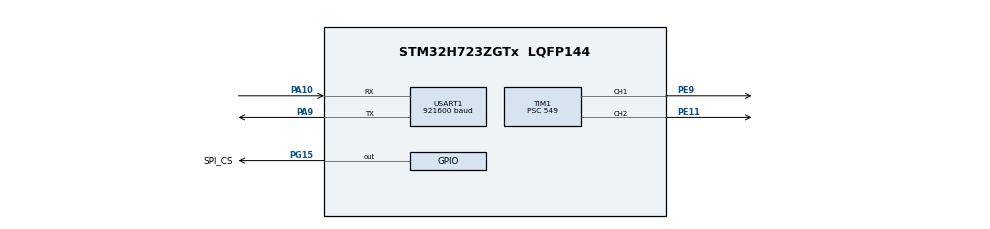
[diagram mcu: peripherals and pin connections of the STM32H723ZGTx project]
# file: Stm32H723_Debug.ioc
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Dma.Request0=USART1_RX
Dma.Request1=USART1_TX
Dma.USART1_RX.0.Direction=DMA_PERIPH_TO_MEMORY
Dma.USART1_RX.0.EventEnable=DISABLE
Dma.USART1_RX.0.FIFOMode=DMA_FIFOMODE_DISABLE
Dma.USART1_RX.0.Instance=DMA1_Stream0
Dma.USART1_RX.0.MemDataAlignment=DMA_MDATAALIGN_BYTE
Dma.USART1_RX.0.MemInc=DMA_MINC_ENABLE
Dma.USART1_RX.0.Mode=DMA_NORMAL
Dma.USART1_RX.0.PeriphDataAlignment=DMA_PDATAALIGN_BYTE
Dma.USART1_RX.0.PeriphInc=DMA_PINC_DISABLE
Dma.USART1_RX.0.Polarity=HAL_DMAMUX_REQ_GEN_RISING
Dma.USART1_RX.0.Priority=DMA_PRIORITY_LOW
Dma.USART1_RX.0.RequestNumber=1
Dma.USART1_RX.0.SignalID=NONE
Dma.USART1_RX.0.SyncEnable=DISABLE
Dma.USART1_RX.0.SyncPolarity=HAL_DMAMUX_SYNC_NO_EVENT
Dma.USART1_RX.0.SyncRequestNumber=1
Dma.USART1_RX.0.SyncSignalID=NONE
Dma.USART1_TX.1.Direction=DMA_MEMORY_TO_PERIPH
Dma.USART1_TX.1.EventEnable=DISABLE
Dma.USART1_TX.1.FIFOMode=DMA_FIFOMODE_DISABLE
Dma.USART1_TX.1.Instance=DMA1_Stream1
Dma.USART1_TX.1.MemDataAlignment=DMA_MDATAALIGN_BYTE
Dma.USART1_TX.1.MemInc=DMA_MINC_ENABLE
Dma.USART1_TX.1.Mode=DMA_NORMAL
Dma.USART1_TX.1.PeriphDataAlignment=DMA_PDATAALIGN_BYTE
Dma.USART1_TX.1.PeriphInc=DMA_PINC_DISABLE
Dma.USART1_TX.1.Polarity=HAL_DMAMUX_REQ_GEN_RISING
Dma.USART1_TX.1.Priority=DMA_PRIORITY_LOW
Dma.USART1_TX.1.RequestNumber=1
Dma.USART1_TX.1.SignalID=NONE
Dma.USART1_TX.1.SyncEnable=DISABLE
Dma.USART1_TX.1.SyncPolarity=HAL_DMAMUX_SYNC_NO_EVENT
Dma.USART1_TX.1.SyncRequestNumber=1
Dma.USART1_TX.1.SyncSignalID=NONE
FREERTOS.BinarySemaphores01=elog_lock,Dynamic,NULL;elog_async,Dynamic,NULL;elog_dma_lock,Dynamic,NULL
FREERTOS.INCLUDE_vTaskDelayUntil=1
FREERTOS.Tasks01=defaultTask,24,1024,DefaultTask,As weak,NULL,Dynamic,NULL,NULL;testTask,32,512,TestTask,As weak,NULL,Dynamic,NULL,NULL
FREERTOS.configENABLE_FPU=1
FREERTOS.configUSE_NEWLIB_REENTRANT=1
Mcu.Family=STM32H7
Mcu.Name=STM32H723ZGTx
Mcu.Package=LQFP144
NVIC.DMA1_Stream0_IRQn=true\:5\:0\:false\:false\:true\:true\:false\:true\:true
NVIC.DMA1_Stream1_IRQn=true\:5\:0\:false\:false\:true\:true\:false\:true\:true
NVIC.PriorityGroup=NVIC_PRIORITYGROUP_4
NVIC.TIM8_BRK_TIM12_IRQn=true\:15\:0\:false\:false\:true\:false\:false\:true\:true
NVIC.TimeBase=TIM8_BRK_TIM12_IRQn
NVIC.TimeBaseIP=TIM12
NVIC.USART1_IRQn=true\:5\:0\:false\:false\:true\:true\:true\:true\:true
PA10.GPIO_Speed=GPIO_SPEED_FREQ_VERY_HIGH
PA10.Mode=Asynchronous
PA10.Signal=USART1_RX
PA13(JTMS/SWDIO).Mode=Serial_Wire
PA13(JTMS/SWDIO).Signal=DEBUG_JTMS-SWDIO
PA14(JTCK/SWCLK).Mode=Serial_Wire
PA14(JTCK/SWCLK).Signal=DEBUG_JTCK-SWCLK
PA9.GPIO_Speed=GPIO_SPEED_FREQ_VERY_HIGH
PA9.Mode=Asynchronous
PA9.Signal=USART1_TX
PC14-OSC32_IN.Mode=LSE-External-Oscillator
PC14-OSC32_IN.Signal=RCC_OSC32_IN
PC15-OSC32_OUT.Mode=LSE-External-Oscillator
PC15-OSC32_OUT.Signal=RCC_OSC32_OUT
PE11.Signal=S_TIM1_CH2
PE9.Signal=S_TIM1_CH1
PF7.Signal=OCTOSPIM_P1_IO2
PG15.GPIO_Label=SPI_CS
PG15.Signal=GPIO_Output
PG6.Signal=OCTOSPIM_P1_NCS
PG8.GPIO_Speed=GPIO_SPEED_FREQ_VERY_HIGH
PG8.Signal=SPI6_NSS
PH0-OSC_IN.Mode=HSE-External-Oscillator
PH0-OSC_IN.Signal=RCC_OSC_IN
PH1-OSC_OUT.Mode=HSE-External-Oscillator
PH1-OSC_OUT.Signal=RCC_OSC_OUT
ProjectManager.HeapSize=0x1000
ProjectManager.StackSize=0x1000
ProjectManager.TargetToolchain=STM32CubeIDE
RCC.ADCFreq_Value=50390625
RCC.APB1Freq_Value=137500000
RCC.APB2Freq_Value=137500000
RCC.APB3Freq_Value=137500000
RCC.APB4Freq_Value=137500000
RCC.CortexFreq_Value=550000000
RCC.D1PPRE=RCC_APB3_DIV2
RCC.D2PPRE1=RCC_APB1_DIV2
RCC.D2PPRE2=RCC_APB2_DIV2
RCC.D3PPRE=RCC_APB4_DIV2
RCC.DIVM1=10
RCC.DIVN1=220
RCC.DIVP1=1
RCC.DIVQ1=5
RCC.HCLKFreq_Value=275000000
RCC.HPRE=RCC_HCLK_DIV2
RCC.PLLSourceVirtual=RCC_PLLSOURCE_HSE
RCC.RTCClockSelection=RCC_RTCCLKSOURCE_LSE
RCC.SYSCLKFreq_VALUE=550000000
RCC.SYSCLKSource=RCC_SYSCLKSOURCE_PLLCLK
RCC.USBCLockSelection=RCC_USBCLKSOURCE_HSI48
RCC.USBFreq_Value=48000000
SH.S_TIM1_CH1.0=TIM1_CH1,PWM Generation1 CH1
SH.S_TIM1_CH2.0=TIM1_CH2,PWM Generation2 CH2
TIM1.Channel-PWM\ Generation1\ CH1=TIM_CHANNEL_1
TIM1.Channel-PWM\ Generation2\ CH2=TIM_CHANNEL_2
TIM1.Period=100
TIM1.Prescaler=549
TIM1.Pulse-PWM\ Generation1\ CH1=50
TIM1.Pulse-PWM\ Generation2\ CH2=50
USART1.BaudRate=921600
USART1.VirtualMode-Asynchronous=VM_ASYNC
VP_FREERTOS_VS_CMSIS_V2.Mode=CMSIS_V2
VP_SYS_VS_tim12.Mode=TIM12
board=custom

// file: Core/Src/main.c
/* USER CODE BEGIN Header */
/**
  ******************************************************************************
  * @file           : main.c
  * @brief          : Main program body
  ******************************************************************************
  * @attention
  *
  * Copyright (c) 2024 STMicroelectronics.
  * All rights reserved.
  *
  * This software is licensed under terms that can be found in the LICENSE file
  * in the root directory of this software component.
  * If no LICENSE file comes with this software, it is provided AS-IS.
  *
  ******************************************************************************
  */
/* USER CODE END Header */
#include "main.h"
#include "cmsis_os.h"
#include "dma.h"
#include "tim.h"
#include "usart.h"
#include "gpio.h"

void SystemClock_Config(void);
void MX_FREERTOS_Init(void);

int main(void)
{

  /* MCU Configuration--------------------------------------------------------*/

  /* Reset of all peripherals, Initializes the Flash interface and the Systick. */
  HAL_Init();

  /* Configure the system clock */
  SystemClock_Config();

  /* Initialize all configured peripherals */
  MX_GPIO_Init();
  MX_DMA_Init();
  MX_USART1_UART_Init();
  MX_TIM1_Init();
  /* USER CODE BEGIN 2 */
  Main();

  /* USER CODE END 2 */

  /* Init scheduler */
  osKernelInitialize();

  /* Call init function for freertos objects (in cmsis_os2.c) */
  MX_FREERTOS_Init();

  /* Start scheduler */
  osKernelStart();

  /* We should never get here as control is now taken by the scheduler */

  /* Infinite loop */
  while (1)
  {

  }
}

void SystemClock_Config(void)
{
  RCC_OscInitTypeDef RCC_OscInitStruct = {0};
  RCC_ClkInitTypeDef RCC_ClkInitStruct = {0};

  /** Supply configuration update enable
  */
  HAL_PWREx_ConfigSupply(PWR_LDO_SUPPLY);

  /** Configure the main internal regulator output voltage
  */
  __HAL_PWR_VOLTAGESCALING_CONFIG(PWR_REGULATOR_VOLTAGE_SCALE0);

  while(!__HAL_PWR_GET_FLAG(PWR_FLAG_VOSRDY)) {}

  /** Initializes the RCC Oscillators according to the specified parameters
  * in the RCC_OscInitTypeDef structure.
  */
  RCC_OscInitStruct.OscillatorType = RCC_OSCILLATORTYPE_HSE;
  RCC_OscInitStruct.HSEState = RCC_HSE_ON;
  RCC_OscInitStruct.PLL.PLLState = RCC_PLL_ON;
  RCC_OscInitStruct.PLL.PLLSource = RCC_PLLSOURCE_HSE;
  RCC_OscInitStruct.PLL.PLLM = 10;
  RCC_OscInitStruct.PLL.PLLN = 220;
  RCC_OscInitStruct.PLL.PLLP = 1;
  RCC_OscInitStruct.PLL.PLLQ = 5;
  RCC_OscInitStruct.PLL.PLLR = 2;
  RCC_OscInitStruct.PLL.PLLRGE = RCC_PLL1VCIRANGE_1;
  RCC_OscInitStruct.PLL.PLLVCOSEL = RCC_PLL1VCOWIDE;
  RCC_OscInitStruct.PLL.PLLFRACN = 0;
  if (HAL_RCC_OscConfig(&RCC_OscInitStruct) != HAL_OK)
  {
    Error_Handler();
  }

  /** Initializes the CPU, AHB and APB buses clocks
  */
  RCC_ClkInitStruct.ClockType = RCC_CLOCKTYPE_HCLK|RCC_CLOCKTYPE_SYSCLK
                              |RCC_CLOCKTYPE_PCLK1|RCC_CLOCKTYPE_PCLK2
                              |RCC_CLOCKTYPE_D3PCLK1|RCC_CLOCKTYPE_D1PCLK1;
  RCC_ClkInitStruct.SYSCLKSource = RCC_SYSCLKSOURCE_PLLCLK;
  RCC_ClkInitStruct.SYSCLKDivider = RCC_SYSCLK_DIV1;
  RCC_ClkInitStruct.AHBCLKDivider = RCC_HCLK_DIV2;
  RCC_ClkInitStruct.APB3CLKDivider = RCC_APB3_DIV2;
  RCC_ClkInitStruct.APB1CLKDivider = RCC_APB1_DIV2;
  RCC_ClkInitStruct.APB2CLKDivider = RCC_APB2_DIV2;
  RCC_ClkInitStruct.APB4CLKDivider = RCC_APB4_DIV2;

  if (HAL_RCC_ClockConfig(&RCC_ClkInitStruct, FLASH_LATENCY_3) != HAL_OK)
  {
    Error_Handler();
  }
}

void HAL_TIM_PeriodElapsedCallback(TIM_HandleTypeDef *htim)
{
  if (htim->Instance == TIM12) {
    HAL_IncTick();
  }
}

void Error_Handler(void)
{
  __disable_irq();
  while (1)
  {
  }
}

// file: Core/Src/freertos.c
/* USER CODE BEGIN Header */
/**
  ******************************************************************************
  * File Name          : freertos.c
  * Description        : Code for freertos applications
  ******************************************************************************
  * @attention
  *
  * Copyright (c) 2024 STMicroelectronics.
  * All rights reserved.
  *
  * This software is licensed under terms that can be found in the LICENSE file
  * in the root directory of this software component.
  * If no LICENSE file comes with this software, it is provided AS-IS.
  *
  ******************************************************************************
  */
/* USER CODE END Header */

#include "FreeRTOS.h"
#include "task.h"
#include "main.h"
#include "cmsis_os.h"

/* Definitions for defaultTask */
osThreadId_t defaultTaskHandle;
const osThreadAttr_t defaultTask_attributes = {
  .name = "defaultTask",
  .stack_size = 1024 * 4,
  .priority = (osPriority_t) osPriorityNormal,
};
/* Definitions for testTask */
osThreadId_t testTaskHandle;
const osThreadAttr_t testTask_attributes = {
  .name = "testTask",
  .stack_size = 512 * 4,
  .priority = (osPriority_t) osPriorityAboveNormal,
};
/* Definitions for elog_lock */
osSemaphoreId_t elog_lockHandle;
const osSemaphoreAttr_t elog_lock_attributes = {
  .name = "elog_lock"
};
/* Definitions for elog_async */
osSemaphoreId_t elog_asyncHandle;
const osSemaphoreAttr_t elog_async_attributes = {
  .name = "elog_async"
};
/* Definitions for elog_dma_lock */
osSemaphoreId_t elog_dma_lockHandle;
const osSemaphoreAttr_t elog_dma_lock_attributes = {
  .name = "elog_dma_lock"
};

void DefaultTask(void *argument);
void TestTask(void *argument);

void MX_FREERTOS_Init(void); /* (MISRA C 2004 rule 8.1) */

void MX_FREERTOS_Init(void) {

  /* Create the semaphores(s) */
  /* creation of elog_lock */
  elog_lockHandle = osSemaphoreNew(1, 0, &elog_lock_attributes);

  /* creation of elog_async */
  elog_asyncHandle = osSemaphoreNew(1, 0, &elog_async_attributes);

  /* creation of elog_dma_lock */
  elog_dma_lockHandle = osSemaphoreNew(1, 0, &elog_dma_lock_attributes);

  /* Create the thread(s) */
  /* creation of defaultTask */
  defaultTaskHandle = osThreadNew(DefaultTask, NULL, &defaultTask_attributes);

  /* creation of testTask */
  testTaskHandle = osThreadNew(TestTask, NULL, &testTask_attributes);

}

__weak void DefaultTask(void *argument)
{
  for(;;)
  {
    osDelay(1);
  }
}

__weak void TestTask(void *argument)
{
  for(;;)
  {
    osDelay(1);
  }
}
